# STM32MP25_CM33 register map
File version: 1.3
CPU: CM33 r0p1, little endian, MPU, FPU, vendor SysTick, 8 interrupt priority bits
Registers are 32-bit, read-write, reset 0x0 unless marked. A register's access mark holds for its fields unless they carry their own. Offsets are from the block's base; [hi:lo] are bit positions; {n}, {i} and the like mark numbered series; 'fields as' and 'values as' point back to an identical list.

## CA35SS — CA35SS register block
Base 0x48800000
Same registers: CA35SS_S 0x58800000
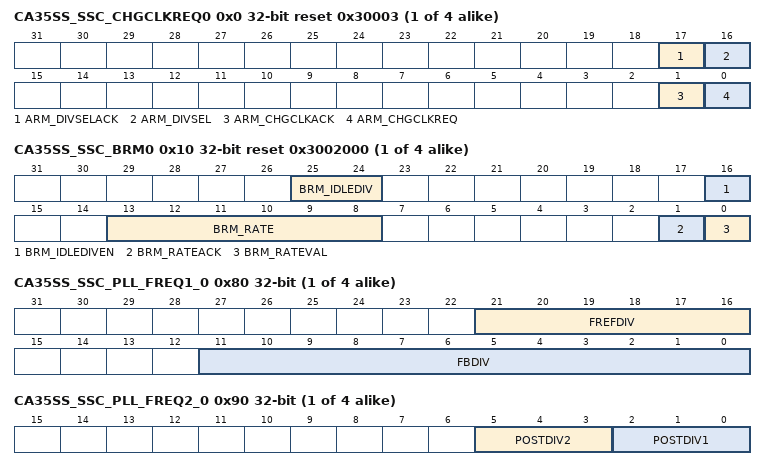
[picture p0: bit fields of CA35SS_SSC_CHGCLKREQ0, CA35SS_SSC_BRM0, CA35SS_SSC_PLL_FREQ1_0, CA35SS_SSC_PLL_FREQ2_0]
{0x0+4i} CA35SS_SSC_CHGCLKREQ{i} reset 0x30003 (i=0..3) — CA35SS SSC CHGCLKREQ register
  [17] ARM_DIVSELACK ro — Defines if ck_cpu_ext2f clock is divided by 2 or not.
    0=ck_cpu1_ext2f divided by two; 1=ck_cpu1_ext2f not divided by two
  [16] ARM_DIVSEL — Selects divider by 2 for ck_cpu1_ext2f clock.
    0=Divide external clock ck_cpu1_ext2f by two; 1=Do not divide external clock ck_cpu1_ext2f
  [1] ARM_CHGCLKACK ro — Indicates clock source.
    0=Cortex-A35 clock is the PLL; 1=Cortex-A35 clock is the external device clock
  [0] ARM_CHGCLKREQ — Selects clock source.
    0=Select internal PLL for Cortex-A35 clock; 1=Select external clock ck_cpu1_ext2f for Cortex-A35 clock
{0x10+4i} CA35SS_SSC_BRM{i} reset 0x3002000 (i=0..3) — CA35SS SSC BRM register
  [25:24] BRM_IDLEDIV — BRM rate when idle mode is entered Must not be modified when BRM_IDLEDIVEN = 1.
    0=CPU clock = BRM clock input / 4; 1=CPU clock = BRM clock input / 8; 2=CPU clock = BRM clock input / 16; 3=CPU clock = BRM clock input / 32
  [16] BRM_IDLEDIVEN — Defines BRM_RATE behaviour in idle mode.
    0=BRM_RATE remains unchanged when the idle mode is entered; 1=BRM_RATE switches to the BRM_IDLEDIV when the idle mode is entered [CPU0(WFI or WFE) and CPU1(WFI or WFE) and L2 idle mode]
  [13:8] BRM_RATE — BRM rate in normal or idle mode when BRM_IDLEDIVEN = 0 1XXXXX: CPU clock = BRM input clock (default reset value) 0YYYYY: CPU clock = BRM input clock * (YYYYY / 32). YYYYY = 00000 is forbidden.
  [1] BRM_RATEACK ro — BRM_RATE status
    0=BRM ready for a new setting; 1=BRM new setting acknowledged
  [0] BRM_RATEVAL — BRM_RATE operation
    0=BRM module is ready for a new setting; 1=Forces the BRM module to sample a new setting
{0x80+4i} CA35SS_SSC_PLL_FREQ1_{i} (i=0..3) — CA35SS SSC PLL FREQ1 register
  [21:16] FREFDIV — Reference divide value
  [11:0] FBDIV — Feedback divide value
{0x90+4i} CA35SS_SSC_PLL_FREQ2_{i} (i=0..3) — CA35SS SSC PLL FREQ2 register
  [5:3] POSTDIV2 — PLL post divide 2 setting (1 to 7) POSTDIV2 = 0 is unused.
  [2:0] POSTDIV1 — PLL post divide 1 setting (1 to 7) POSTDIV1 = 0 is unused.
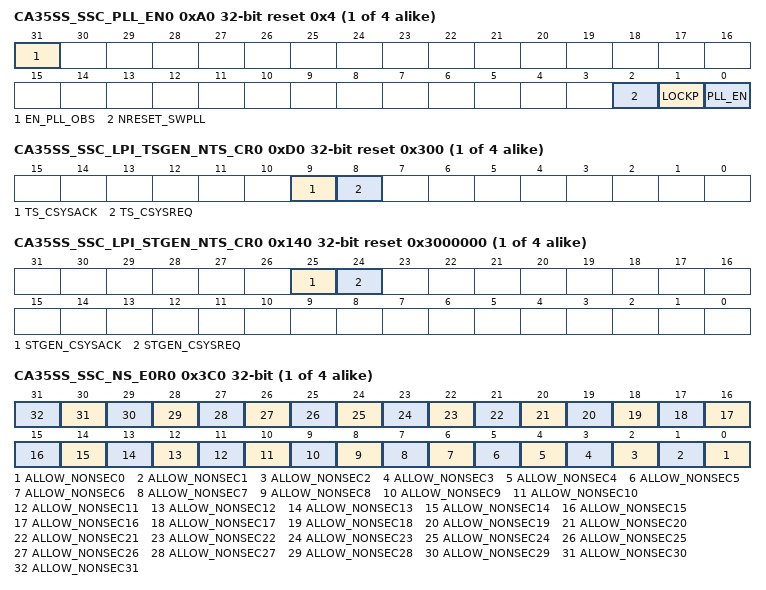
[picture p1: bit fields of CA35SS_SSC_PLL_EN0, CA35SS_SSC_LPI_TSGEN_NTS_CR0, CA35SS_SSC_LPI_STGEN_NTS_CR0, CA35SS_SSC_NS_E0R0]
{0xA0+4i} CA35SS_SSC_PLL_EN{i} reset 0x4 (i=0..3) — CA35SS SSC PLL enable register
  [31] EN_PLL_OBS — PLL observation output status
    0=PLL is not observable; 1=Enable PLL output observation in functional mode (PLL clock is divided by 42)
  [2] NRESET_SWPLL — Clock switcher reset state
    0=Clock switcher logic clocked by the PLL under reset; 1=Clock switcher logic not in reset
  [1] LOCKP ro — PLLL lock state
    0=PLL not locked; 1=PLL locked
  [0] PLL_EN — PLL enable for Cortex-A35
    0=PLL disabled; 1=PLL enabled
{0xD0+4i} CA35SS_SSC_LPI_TSGEN_NTS_CR{i} reset 0x300 (i=0..3) — CA35SS SSC LPI TSGEN NTS CR register
  [9] TS_CSYSACK ro — Timestamp asynchronous bridge power status
    0=Timestamp asynchronous bridge powered down; 1=Timestamp asynchronous bridge powered up
  [8] TS_CSYSREQ — Timestamp asynchronous bridge power request
    0=Request timestamp asynchronous bridge to be powered down (csysreq is active low); 1=Request timestamp asynchronous bridge to be powered up
0x100 CA35SS_SSC_C0_SMP ro — CA35SS SSC core 0 SMP register
  [16] SMPEN — Indicates whether core 0 takes part in coherency.
    0=Data coherency disabled; 1=Data coherency enabled
0x110 CA35SS_SSC_C1_SMP ro — CA35SS SSC core 1 SMP register
  [16] SMPEN — Indicates whether core 1 takes part in coherency.
    0=Data coherency disabled; 1=Data coherency enabled
{0x140+4i} CA35SS_SSC_LPI_STGEN_NTS_CR{i} reset 0x3000000 (i=0..3) — CA35SS SSC LPI STGEN NTS CR register
  [25] STGEN_CSYSACK ro — STGEN asynchronous bridge power status
    0=STGEN asynchronous bridge is powered down; 1=STGEN asynchronous bridge is powered up
  [24] STGEN_CSYSREQ — STGEN asynchronous bridge power request
    0=Request STGEN asynchronous bridge to be powered down (csysreq is active low); 1=Request STGEN asynchronous bridge to be powered up
{0x3C0+4i} CA35SS_SSC_NS_E0R{i} (i=0..3) — CA35SS SSC NS enable 0 register
  [all] fields
    0=SSC register access is secure; 1=SSC register access is non-secure
  [n] ALLOW_NONSEC{n} (n=0..31) — SSC register security settings Bit[n] configures the security settings of the SSC register at address 16 * n up to 0x1F0.
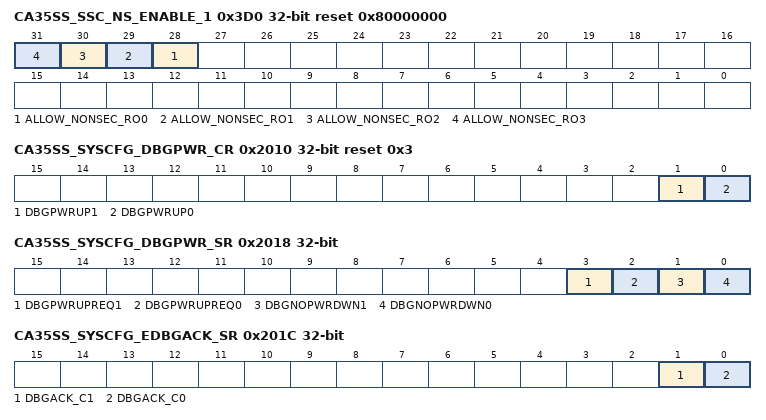
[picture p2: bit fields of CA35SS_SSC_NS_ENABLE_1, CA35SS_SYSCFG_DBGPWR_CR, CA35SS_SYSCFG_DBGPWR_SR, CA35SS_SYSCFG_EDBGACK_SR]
0x3D0 CA35SS_SSC_NS_ENABLE_1 ro reset 0x80000000
  [all] fields
    values as the fields of CA35SS_SSC_NS_E0R0
  [n+28] ALLOW_NONSEC_RO{n} (n=0..3) — SSC register security settings Bit[n] indicates the security settings of the SSC register from 0x3C0 (bit 28) up to 0x3F0 (bit 31).
0x2000 CA35SS_SYSCFG_ETR_LPI_CR reset 0x1 — CA35SS ETR low-power interface control register
  [0] ETR_CSYSREQ
    0=Request ETR AXI bus to be stalled (csysreq is active low); 1=Request ETR AXI activity to resume
0x2004 CA35SS_SYSCFG_ETR_LPI_SR ro — CA35SS ETR low-power interface status register
  [0] ETR_CSYSACK
    0=ETR AXI transactions stalled; 1=ETR AXI transactions not stalled
0x2008 CA35SS_SYSCFG_STM_NSGUAREN_CR reset 0x1 — CA35SS STM non-secure guaranteed access register
  [0] STM_NSGUAREN
    0=Non-secure access is not guaranteed to be traced. The AXI write data channel does not stall when the STM is unable to trace the transaction immediately. The STM discards write data ifitcannot be traced.; 1=Non-secure access is guaranteed to be traced, that is the AXI write data channel stalls until theSTM can emit the trace. This is obviously intrusive with respect to the real time.
0x200C CA35SS_SYSCFG_TRACE_CLK_DIV_CR — CA35SS TPIU export clock divider register
  [5:0] TRACE_CLK_DIV_VALUE — 0x1 to 0x3F: Divider ratio from 2 to 64
    0=Divider bypassed
0x2010 CA35SS_SYSCFG_DBGPWR_CR reset 0x3 — CA35SS Cortex-A35 core debug power mode register
  [1] DBGPWRUP1
    0=Core 1 debug powered down; 1=Core 1 debug powered up
  [0] DBGPWRUP0
    0=Core 0 debug powered down; 1=Core 0 debug powered up
0x2014 CA35SS_SYSCFG_DBGL1RSTDISABLE_CR — CA35SS Cortex-A35 L1 data cache register
  [0] DBGL1RSTDIS
    0=Enable automatic invalidation of L1 data cache on reset; 1=Disable automatic invalidation of L1 data cache on reset
0x2018 CA35SS_SYSCFG_DBGPWR_SR ro — CA35SS Cortex-A35 debug power register
  [3] DBGPWRUPREQ1
    0=Debug does not request that the core 1 is powered-up; 1=Debug requests that the core 1 is powered-up
  [2] DBGPWRUPREQ0
    0=Debug does not request that the core 0 is powered-up; 1=Debug requests that the core 0 is powered-up
  [1] DBGNOPWRDWN1
    0=Debug does not request that the core 1 stays powered-up; 1=Debug requests that the core 1 stays powered-up
  [0] DBGNOPWRDWN0
    0=Debug does not request that the core 0 stays powered-up; 1=Debug requests that the core 0 stays powered-up
0x201C CA35SS_SYSCFG_EDBGACK_SR ro — CA35SS Cortex-A35 debug mode status register
  [1] DBGACK_C1
    0=Core 1 is not in debug mode; 1=Core 1 is halted in debug mode
  [0] DBGACK_C0
    0=Core 0 is not in debug mode; 1=Core 0 is halted in debug mode
0x2020 CA35SS_SYSCFG_GIC_CFGR — GIC configuration register
  [0] GIC_4KNOT64K
    0=Use the GIC in a 64-Kbyte translation granule system; 1=Use the GIC in a 4-Kbyte translation granule system
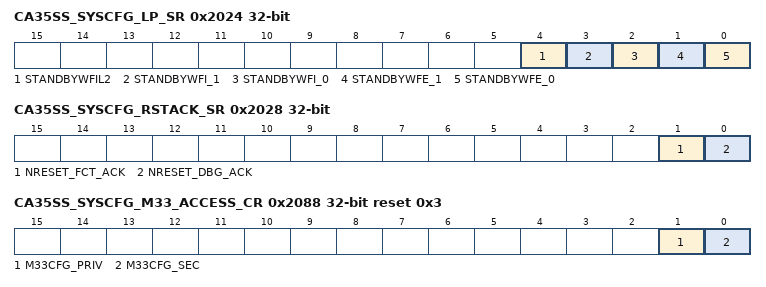
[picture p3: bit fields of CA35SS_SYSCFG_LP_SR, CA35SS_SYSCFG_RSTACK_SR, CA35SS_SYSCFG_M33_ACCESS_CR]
0x2024 CA35SS_SYSCFG_LP_SR ro — Cortex-A35 low-power status register
  [4] STANDBYWFIL2
    0=L2 memory system not in WFI low-power state; 1=L2 memory system in WFI low-power state
  [3] STANDBYWFI_1
    0=Core 1 not in WFI low-power state; 1=Core 1 in WFI low-power state
  [2] STANDBYWFI_0
    0=Core 0 not in WFI low-power state; 1=Core 0 in WFI low-power state
  [1] STANDBYWFE_1
    0=Core 1 not in WFE low-power state; 1=Core 1 in WFE low-power state
  [0] STANDBYWFE_0
    0=Core 0 not in WFE low-power state; 1=Core 0 in WFE low-power state
0x2028 CA35SS_SYSCFG_RSTACK_SR ro — Cortex-A35 reset status register
  [1] NRESET_FCT_ACK
    0=Functional reset active; 1=Functional reset inactive
  [0] NRESET_DBG_ACK
    0=Debug reset active; 1=Debug reset inactive
0x2080 CA35SS_SYSCFG_AARCH_MODE_CR — CA35SS architecture mode register
  [0] AA64NAA32
    0=Cortex-A35 cores boot in 32-bit mode; 1=Cortex-A35 cores boot in 64-bit mode
0x2084 CA35SS_SYSCFG_VBAR_CR — CA35SS reset vector register
  [31:2] RVBARADDRL — Set the value of reset vector at the boundaries of the Cortex-A35 cores.
0x2088 CA35SS_SYSCFG_M33_ACCESS_CR reset 0x3 — Cortex-M33 boot register access rights register
  [1] M33CFG_PRIV
    0=Cortex-M33 boot option registers are accessed in non-privilege and privilege modes; 1=Cortex-M33 boot option registers are accessed in privilege mode only
  [0] M33CFG_SEC
    0=Cortex-M33 boot option registers are accessed in non-secure and secure modes; 1=Cortex-M33 boot option registers are accessed in secure mode only
0x20A0 CA35SS_SYSCFG_M33_TZEN_CR reset 0x1 — Cortex-M33 secure extension enable register
  [0] CFG_SECEXT
    0=Armv8-M TrustZone support disabled; 1=Armv8-M TrustZone support enabled
0x20A4 CA35SS_SYSCFG_M33_INITSVTOR_CR reset 0xE080000 — Cortex-M33 secure vector address register
  [31:7] INITSVTOR — Secure vector table offset
0x20A8 CA35SS_SYSCFG_M33_INITNSVTOR_CR reset 0xA080000 — Cortex-M33 non-secure vector address register
  [31:7] INITNSVTOR — Non-secure vector table offset
